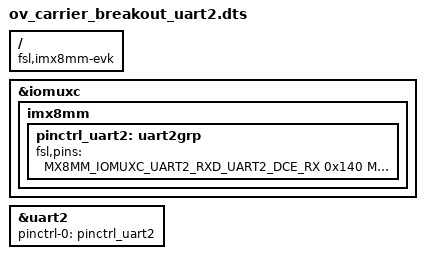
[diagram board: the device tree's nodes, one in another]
/**
 * Portenta-M8 dtb overlay file
 * Arduino 2021
 * Enable UART2 on Arduino Breakout carrier board
 * no RTS CTS only TX RX
 */

/dts-v1/;
/plugin/;

#include "imx8mm-pinfunc.h"

/ {
	compatible = "fsl,imx8mm-evk", "fsl,imx8mm";

	fragment@0 {
		target = <&iomuxc>;
		__overlay__ {
			imx8mm {
				pinctrl_uart2: uart2grp {
					fsl,pins = <
						MX8MM_IOMUXC_UART2_RXD_UART2_DCE_RX       0x140
						MX8MM_IOMUXC_UART2_TXD_UART2_DCE_TX       0x140
					>;
				};
			};
		};
	};

	fragment@1 {
		target = <&uart2>;
		__overlay__ {
			pinctrl-names = "default";
			pinctrl-0 = <&pinctrl_uart2>;
			status = "okay";
		};
	};
};
